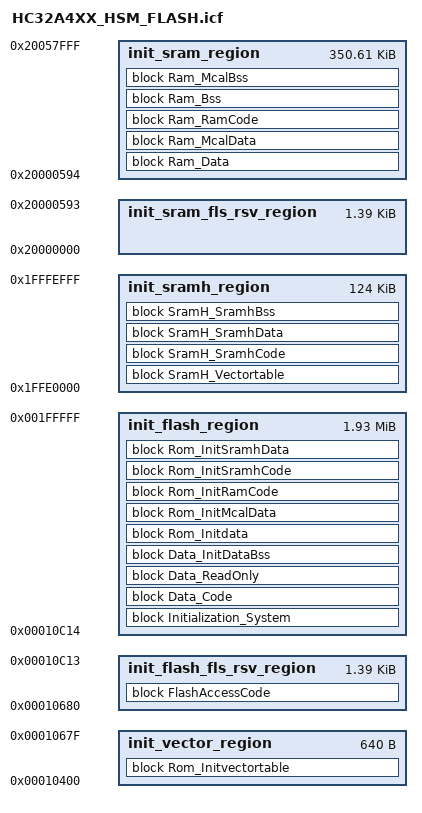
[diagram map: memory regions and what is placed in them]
/***********************************************************************************************************************
 * Project Name: XHSC AUTOSAR MCAL
 * File Name: HC32A4XX.icf
 *
 * Description: Implementation of 
 *              AutoSAR Version:         4.4.0
 *
 *
 * Copyright (c) 2022 - 2026 Xiaohua Semiconductor Co., Ltd.
 * 
 * All rights reserved.
 *
 * This software is licensed by XHSC PLATFORM SOFTWARE LICENSE AGREEMENT (the "License"). By downloading, installing, or
 * using the Software, you indicate that you accept the terms of the License, and you acknowledge that you have the
 * authority, for yourself or on behalf of your company, to bind your company to these terms. If you do not agree to all
 * of the terms of this License, you should not download or install the Software.
 *
 **********************************************************************************************************************/


/* Memory Regions */
define symbol __ICFEDIT_region_VECTOR_start__            = 0x00010400;    /* 640B */
define symbol __ICFEDIT_region_VECTOR_end__              = 0x0001067F;

define symbol __ICFEDIT_region_FLS_RSV_FLASH_start__     = 0x00010680;    /* 1428B for acfls */
define symbol __ICFEDIT_region_FLS_RSV_FLASH_end__       = 0x00010C13;

define symbol __ICFEDIT_region_FLASH_start__             = 0x00010C14;    /* 1980.98KB */
define symbol __ICFEDIT_region_FLASH_end__               = 0x001FFFFF;

define symbol __ICFEDIT_region_SRAMH_start__             = 0x1FFE0000;    /* 124KB */
define symbol __ICFEDIT_region_SRAMH_end__               = 0x1FFFEFFF;

define symbol __ICFEDIT_region_SRAMH_STACK_start__       = 0x1FFFF000;    /* 4KB */
define symbol __ICFEDIT_region_SRAMH_STACK_end__         = 0x20000000;

define symbol __ICFEDIT_region_FLS_RSV_RAM_start__       = 0x20000000;    /* 1428B for acfls ram */
define symbol __ICFEDIT_region_FLS_RSV_RAM_end__         = 0x20000593;

define symbol __ICFEDIT_region_SRAM1_3_start__           = 0x20000594;    /* 350.6KB */
define symbol __ICFEDIT_region_SRAM1_3_end__             = 0x20057FFF;

/* Fls module access code support */
define exported symbol __FLS_AC_ERASE_START_ADDR_IN_ROM    = __ICFEDIT_region_FLS_RSV_FLASH_start__;
define exported symbol __FLS_AC_ERASE_END_ADDR_IN_ROM      = __ICFEDIT_region_FLS_RSV_FLASH_end__;
define exported symbol __FLS_AC_ERASE_CODE_SIZE_IN_ROM     = (__ICFEDIT_region_FLS_RSV_FLASH_end__ - __ICFEDIT_region_FLS_RSV_FLASH_start__ +3 )/4;

define exported symbol __FLS_AC_WRITE_START_ADDR_IN_ROM  = __ICFEDIT_region_FLS_RSV_FLASH_start__;
define exported symbol __FLS_AC_WRITE_END_ADDR_IN_ROM    = __ICFEDIT_region_FLS_RSV_FLASH_end__ ;
define exported symbol __FLS_AC_WRITE_CODE_SIZE_IN_ROM   = (__ICFEDIT_region_FLS_RSV_FLASH_end__ - __ICFEDIT_region_FLS_RSV_FLASH_start__ +3 )/4;

define exported symbol __FLS_AC_BLANKREAD_START_ADDR_IN_ROM  = __ICFEDIT_region_FLS_RSV_FLASH_start__;
define exported symbol __FLS_AC_BLANKREAD_END_ADDR_IN_ROM    = __ICFEDIT_region_FLS_RSV_FLASH_end__ ;
define exported symbol __FLS_AC_BLANKREAD_CODE_SIZE_IN_ROM   = (__ICFEDIT_region_FLS_RSV_FLASH_end__ - __ICFEDIT_region_FLS_RSV_FLASH_start__ +3 )/4;

define exported symbol __FLS_AC_ERASE_FUNC_PTR_IN_RAM = __ICFEDIT_region_FLS_RSV_RAM_start__;
define exported symbol __FLS_AC_WRITE_FUNC_PTR_IN_RAM = __ICFEDIT_region_FLS_RSV_RAM_start__;
define exported symbol __FLS_AC_BLANKREAD_FUNC_PTR_IN_RAM = __ICFEDIT_region_FLS_RSV_RAM_start__;

define exported symbol __INIT_SRAM_START     = __ICFEDIT_region_FLS_RSV_RAM_start__;
define exported symbol __INIT_SRAM_END       = __ICFEDIT_region_SRAM1_3_end__;

define exported symbol __INIT_SRAMH_START     = __ICFEDIT_region_SRAMH_start__;
define exported symbol __INIT_SRAMH_END       = __ICFEDIT_region_SRAMH_STACK_end__-1;

define exported symbol __STACK_END      = __ICFEDIT_region_SRAMH_STACK_start__;
define exported symbol __STACK_START    = __ICFEDIT_region_SRAMH_STACK_end__;

define exported symbol __RAM_INIT       = 1;

define memory mem with size = 4G;
define region init_vector_region        = mem:[from __ICFEDIT_region_VECTOR_start__ to __ICFEDIT_region_VECTOR_end__];
define region init_flash_fls_rsv_region = mem:[from __ICFEDIT_region_FLS_RSV_FLASH_start__ to __ICFEDIT_region_FLS_RSV_FLASH_end__];
define region init_flash_region         = mem:[from __ICFEDIT_region_FLASH_start__ to __ICFEDIT_region_FLASH_end__];
define region init_sram_region          = mem:[from __ICFEDIT_region_SRAM1_3_start__ to __ICFEDIT_region_SRAM1_3_end__];
define region init_sram_fls_rsv_region  = mem:[from __ICFEDIT_region_FLS_RSV_RAM_start__ to __ICFEDIT_region_FLS_RSV_RAM_end__];
define region init_sramh_region         = mem:[from __ICFEDIT_region_SRAMH_start__ to __ICFEDIT_region_SRAMH_end__];

define exported symbol __VTABLE_INIT = start(init_vector_region);

initialize manually {
                     section .data,
                     section .mcal_data.*,
                     section .ramcode*,
                     section .intvec,
                     section .mcal_text.fast.*,
                     section .mcal_data.fast.*                     
                    };
do not initialize  {
                    section .bss,
                    section .mcal_bss.*,
                    section .mcal_bss.fast.*
                   };

keep {symbol l_SystemICG0Value_u32, symbol l_SystemICG1Value_u32, symbol l_SystemICG3Value_u32, symbol l_SystemICG8AValue_u32,
      symbol l_SystemICG8BValue_u32, symbol l_SystemICG8CValue_u32, symbol l_SystemICGReserve11Value_u32, symbol l_SystemICGReserve12Value_u32, symbol l_SystemICGReserve13Value_u32};

/* Flash region */
define block Initialization_System with fixed order                   { section .startup, section .systeminit };
define block Data_Code with fixed order                               { section .text, section .mcal_text.* };
define block Data_ReadOnly with fixed order                           { section .rodata, section .mcal_const_cfg.*, section .mcal_const.* };
define block Data_InitDataBss with fixed order                        { section .init_table, section .zero_table, section .iar.* };
define block Rom_Initvectortable with fixed order, alignment = 1024   { section .intvec_init };
define block Rom_Initdata with fixed order                            { section .data_init };
define block Rom_InitMcalData with fixed order                        { section .mcal_data.*_init };
define block Rom_InitRamCode with fixed order                         { section .ramcode*_init };
define block Rom_InitSramhCode with fixed order, alignment = 4        { section .mcal_text.fast.*_init };
define block Rom_InitSramhData with fixed order, alignment = 4        { section .mcal_data.fast.*_init };
define block FlashAccessCode with fixed order                         { section .acfls_code_rom };

/* Sram1_3 region */
define block Ram_Data with fixed order                      { section .data };
define block Ram_McalData with fixed order                  { section .mcal_data.* };
define block Ram_RamCode with fixed order                   { section .ramcode* };
define block Ram_Bss with fixed order, alignment = 4        { section .bss };
define block Ram_McalBss with fixed order, alignment = 4    { section .mcal_bss.* };

/* SramH region */
define block SramH_Vectortable with fixed order, alignment = 1024            { section .intvec };
define block SramH_SramhCode with fixed order, alignment = 4                 { section .mcal_text.fast.* };
define block SramH_SramhData with fixed order, alignment = 4                 { section .mcal_data.fast.* };
define block SramH_SramhBss with fixed order, alignment = 4                  { section .mcal_bss.fast.* };

place in init_vector_region           { block Rom_Initvectortable };
place in init_flash_region            { block Initialization_System, block Data_Code, block Data_ReadOnly, block Data_InitDataBss, block Rom_Initdata, block Rom_InitMcalData, block Rom_InitRamCode, block Rom_InitSramhCode, block Rom_InitSramhData };
place in init_flash_fls_rsv_region    { block FlashAccessCode };
place in init_sram_region             { block Ram_Data, block Ram_McalData, block Ram_RamCode, block Ram_Bss, block Ram_McalBss };
place in init_sramh_region            { block SramH_Vectortable, block SramH_SramhCode, block SramH_SramhData, block SramH_SramhBss };
